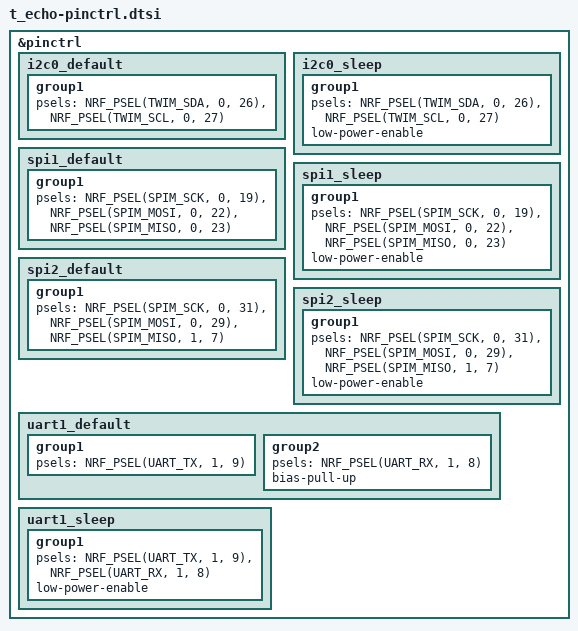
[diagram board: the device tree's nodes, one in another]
/*
 * SPDX-License-Identifier: GPL-3.0-or-later
 * SPDX-FileCopyrightText: The contributors to the LICHEN project
 *
 * T-Echo V1 pin assignments, sourced from LilyGo schematics and
 * cross-checked against the Meshtastic firmware variant.h.
 */

&pinctrl {
	/* I2C0: PCF8563 RTC — SDA=P0.26, SCL=P0.27 */
	i2c0_default: i2c0_default {
		group1 {
			psels = <NRF_PSEL(TWIM_SDA, 0, 26)>,
				<NRF_PSEL(TWIM_SCL, 0, 27)>;
		};
	};
	i2c0_sleep: i2c0_sleep {
		group1 {
			psels = <NRF_PSEL(TWIM_SDA, 0, 26)>,
				<NRF_PSEL(TWIM_SCL, 0, 27)>;
			low-power-enable;
		};
	};

	/*
	 * SPI1: SX1262 LoRa radio
	 *   SCK=P0.19  MOSI=P0.22  MISO=P0.23
	 *   CS=P0.24 (GPIO, via cs-gpios in SPI node)
	 */
	spi1_default: spi1_default {
		group1 {
			psels = <NRF_PSEL(SPIM_SCK,  0, 19)>,
				<NRF_PSEL(SPIM_MOSI, 0, 22)>,
				<NRF_PSEL(SPIM_MISO, 0, 23)>;
		};
	};
	spi1_sleep: spi1_sleep {
		group1 {
			psels = <NRF_PSEL(SPIM_SCK,  0, 19)>,
				<NRF_PSEL(SPIM_MOSI, 0, 22)>,
				<NRF_PSEL(SPIM_MISO, 0, 23)>;
			low-power-enable;
		};
	};

	/*
	 * SPI2: GDEW0154M10 e-ink display
	 *   SCK=P0.31  MOSI=P0.29  MISO=P1.07 (not connected, required by driver)
	 *   CS=P0.30  DC=P0.28  RESET=P0.02  BUSY=P0.03
	 */
	spi2_default: spi2_default {
		group1 {
			psels = <NRF_PSEL(SPIM_SCK,  0, 31)>,
				<NRF_PSEL(SPIM_MOSI, 0, 29)>,
				<NRF_PSEL(SPIM_MISO, 1,  7)>;
		};
	};
	spi2_sleep: spi2_sleep {
		group1 {
			psels = <NRF_PSEL(SPIM_SCK,  0, 31)>,
				<NRF_PSEL(SPIM_MOSI, 0, 29)>,
				<NRF_PSEL(SPIM_MISO, 1,  7)>;
			low-power-enable;
		};
	};

	/*
	 * UART1: L76K GPS module
	 *   TX=P1.09 (nRF → GPS)  RX=P1.08 (GPS → nRF)
	 */
	uart1_default: uart1_default {
		group1 {
			psels = <NRF_PSEL(UART_TX, 1, 9)>;
		};
		group2 {
			psels = <NRF_PSEL(UART_RX, 1, 8)>;
			bias-pull-up;
		};
	};
	uart1_sleep: uart1_sleep {
		group1 {
			psels = <NRF_PSEL(UART_TX, 1, 9)>,
				<NRF_PSEL(UART_RX, 1, 8)>;
			low-power-enable;
		};
	};
};
